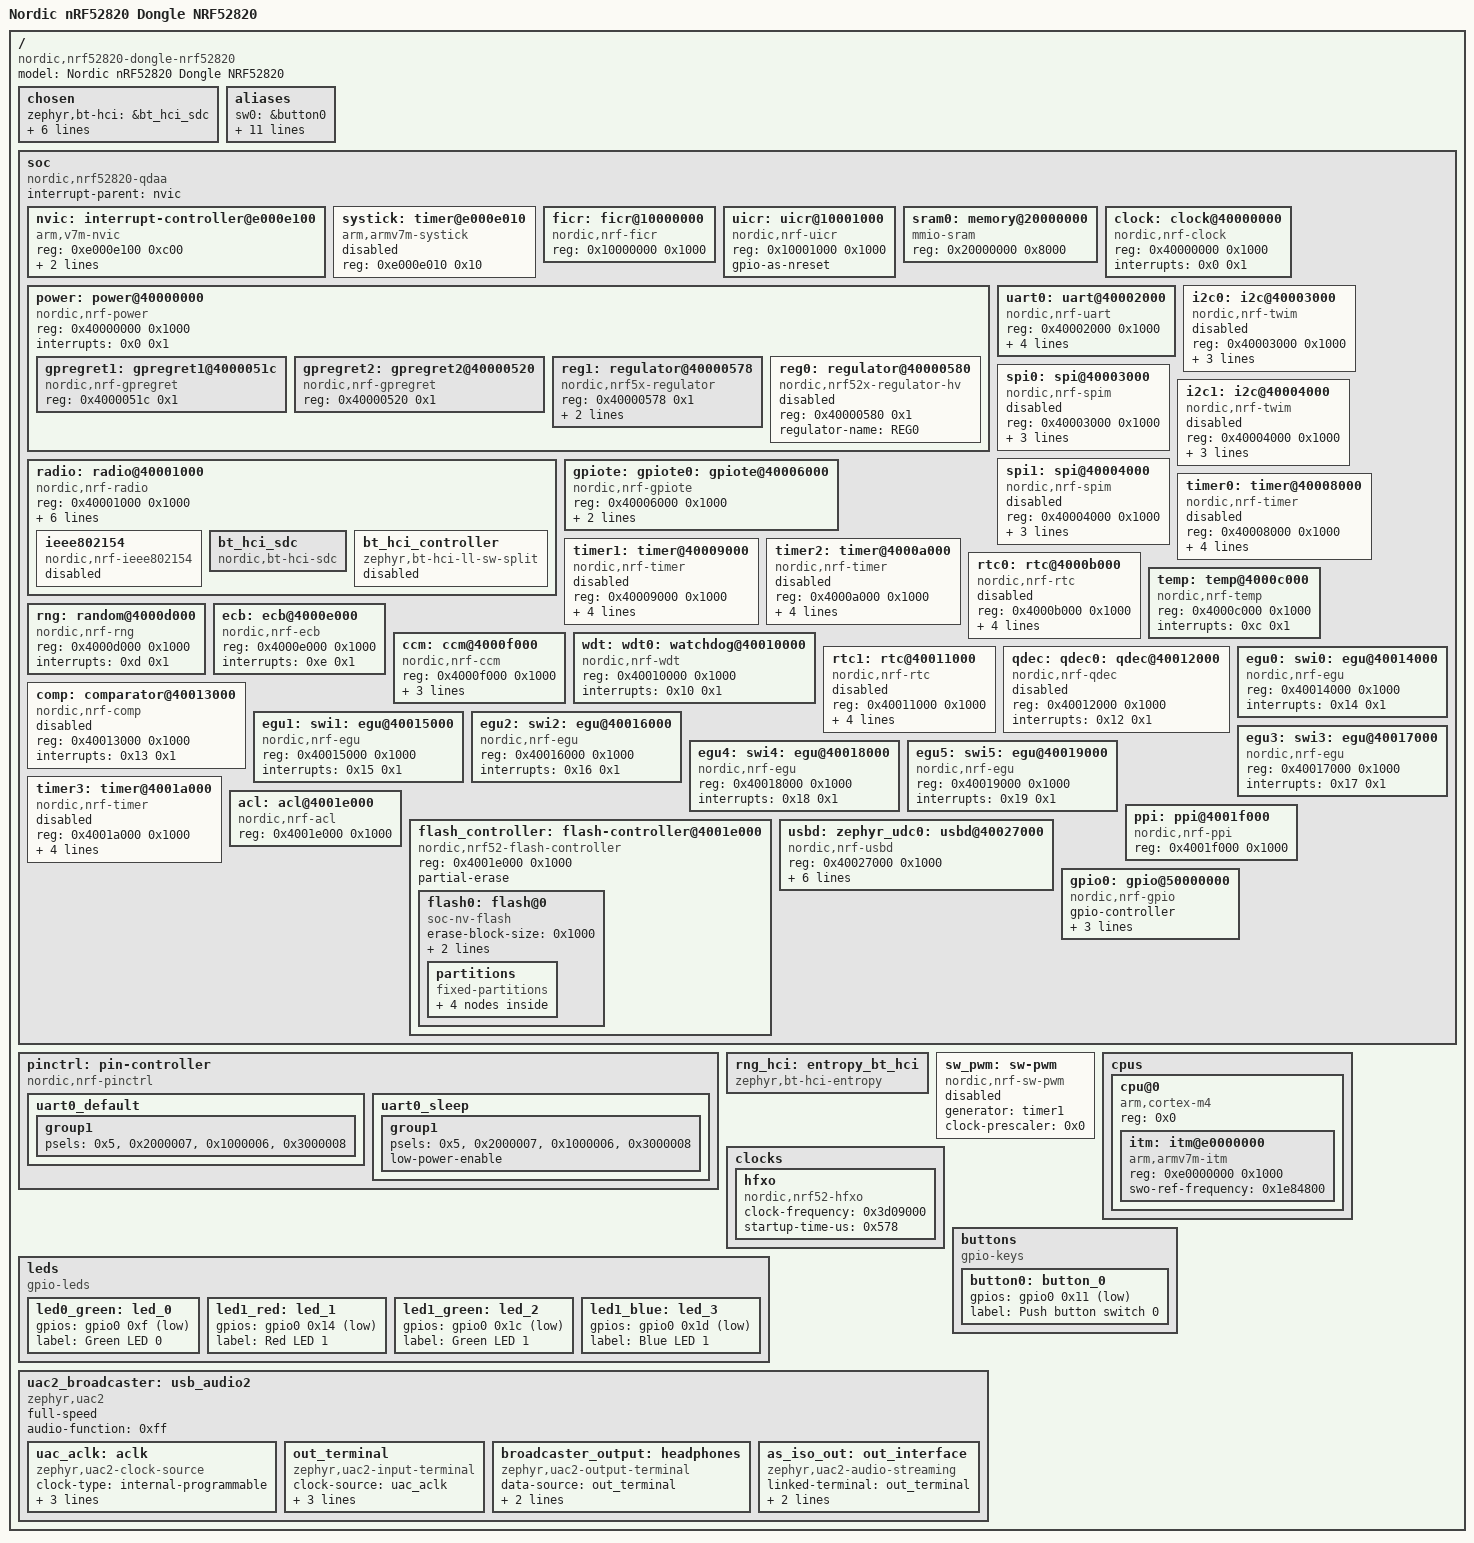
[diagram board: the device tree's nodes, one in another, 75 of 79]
/dts-v1/;

/* node '/' defined in zephyr\dts\common\skeleton.dtsi:9 */
/ {
	#address-cells = < 0x1 >;                       /* in zephyr\dts\common\skeleton.dtsi:10 */
	#size-cells = < 0x1 >;                          /* in zephyr\dts\common\skeleton.dtsi:11 */
	model = "Nordic nRF52820 Dongle NRF52820";      /* in nrf\boards\nordic\nrf52820dongle\nrf52820dongle_nrf52820.dts:11 */
	compatible = "nordic,nrf52820-dongle-nrf52820"; /* in nrf\boards\nordic\nrf52820dongle\nrf52820dongle_nrf52820.dts:12 */

	/* node '/chosen' defined in zephyr\dts\common\skeleton.dtsi:12 */
	chosen {
		zephyr,bt-hci = &bt_hci_sdc;                 /* in zephyr\dts\arm\nordic\nrf52820.dtsi:14 */
		zephyr,entropy = &rng;                       /* in zephyr\dts\arm\nordic\nrf52820.dtsi:15 */
		zephyr,flash-controller = &flash_controller; /* in zephyr\dts\arm\nordic\nrf52820.dtsi:16 */
		zephyr,console = &uart0;                     /* in nrf\boards\nordic\nrf52820dongle\nrf52820dongle_nrf52820.dts:15 */
		zephyr,sram = &sram0;                        /* in nrf\boards\nordic\nrf52820dongle\nrf52820dongle_nrf52820.dts:16 */
		zephyr,flash = &flash0;                      /* in nrf\boards\nordic\nrf52820dongle\nrf52820dongle_nrf52820.dts:17 */
		zephyr,code-partition = &slot0_partition;    /* in nrf\boards\nordic\nrf52820dongle\nrf52820dongle_nrf52820.dts:18 */
	};

	/* node '/aliases' defined in zephyr\dts\common\skeleton.dtsi:13 */
	aliases {
		sw0 = &button0;             /* in nrf\boards\nordic\nrf52820dongle\nrf52820dongle_nrf52820.dts:51 */
		led0 = &led0_green;         /* in nrf\boards\nordic\nrf52820dongle\nrf52820dongle_nrf52820.dts:52 */
		led1 = &led1_red;           /* in nrf\boards\nordic\nrf52820dongle\nrf52820dongle_nrf52820.dts:53 */
		led2 = &led1_green;         /* in nrf\boards\nordic\nrf52820dongle\nrf52820dongle_nrf52820.dts:54 */
		led3 = &led1_blue;          /* in nrf\boards\nordic\nrf52820dongle\nrf52820dongle_nrf52820.dts:55 */
		led0-green = &led0_green;   /* in nrf\boards\nordic\nrf52820dongle\nrf52820dongle_nrf52820.dts:56 */
		led1-red = &led1_red;       /* in nrf\boards\nordic\nrf52820dongle\nrf52820dongle_nrf52820.dts:57 */
		led1-green = &led1_green;   /* in nrf\boards\nordic\nrf52820dongle\nrf52820dongle_nrf52820.dts:58 */
		led1-blue = &led1_blue;     /* in nrf\boards\nordic\nrf52820dongle\nrf52820dongle_nrf52820.dts:59 */
		mcuboot-button0 = &button0; /* in nrf\boards\nordic\nrf52820dongle\nrf52820dongle_nrf52820.dts:60 */
		mcuboot-led0 = &led1_blue;  /* in nrf\boards\nordic\nrf52820dongle\nrf52820dongle_nrf52820.dts:61 */
		watchdog0 = &wdt0;          /* in nrf\boards\nordic\nrf52820dongle\nrf52820dongle_nrf52820.dts:62 */
	};

	/* node '/soc' defined in zephyr\dts\arm\armv7-m.dtsi:6 */
	soc {
		#address-cells = < 0x1 >;            /* in zephyr\dts\arm\armv7-m.dtsi:7 */
		#size-cells = < 0x1 >;               /* in zephyr\dts\arm\armv7-m.dtsi:8 */
		compatible = "nordic,nrf52820-qdaa",
		             "nordic,nrf52820",
		             "nordic,nrf52",
		             "simple-bus";           /* in zephyr\dts\arm\nordic\nrf52820_qdaa.dtsi:20 */
		interrupt-parent = < &nvic >;        /* in zephyr\dts\arm\armv7-m.dtsi:10 */
		ranges;                              /* in zephyr\dts\arm\armv7-m.dtsi:11 */

		/* node '/soc/interrupt-controller@e000e100' defined in zephyr\dts\arm\armv7-m.dtsi:13 */
		nvic: interrupt-controller@e000e100 {
			#address-cells = < 0x1 >;            /* in zephyr\dts\arm\armv7-m.dtsi:14 */
			compatible = "arm,v7m-nvic";         /* in zephyr\dts\arm\armv7-m.dtsi:15 */
			reg = < 0xe000e100 0xc00 >;          /* in zephyr\dts\arm\armv7-m.dtsi:16 */
			interrupt-controller;                /* in zephyr\dts\arm\armv7-m.dtsi:17 */
			#interrupt-cells = < 0x2 >;          /* in zephyr\dts\arm\armv7-m.dtsi:18 */
			arm,num-irq-priority-bits = < 0x3 >; /* in zephyr\dts\arm\nordic\nrf52820.dtsi:433 */
			phandle = < 0x1 >;                   /* in zephyr\dts\arm\armv7-m.dtsi:10 */
		};

		/* node '/soc/timer@e000e010' defined in zephyr\dts\arm\armv7-m.dtsi:21 */
		systick: timer@e000e010 {
			compatible = "arm,armv7m-systick"; /* in zephyr\dts\arm\armv7-m.dtsi:22 */
			reg = < 0xe000e010 0x10 >;         /* in zephyr\dts\arm\armv7-m.dtsi:23 */
			status = "disabled";               /* in zephyr\dts\arm\nordic\nrf52820.dtsi:438 */
		};

		/* node '/soc/ficr@10000000' defined in zephyr\dts\arm\nordic\nrf52820.dtsi:48 */
		ficr: ficr@10000000 {
			compatible = "nordic,nrf-ficr"; /* in zephyr\dts\arm\nordic\nrf52820.dtsi:49 */
			reg = < 0x10000000 0x1000 >;    /* in zephyr\dts\arm\nordic\nrf52820.dtsi:50 */
			#nordic,ficr-cells = < 0x1 >;   /* in zephyr\dts\arm\nordic\nrf52820.dtsi:51 */
			status = "okay";                /* in zephyr\dts\arm\nordic\nrf52820.dtsi:52 */
		};

		/* node '/soc/uicr@10001000' defined in zephyr\dts\arm\nordic\nrf52820.dtsi:55 */
		uicr: uicr@10001000 {
			compatible = "nordic,nrf-uicr"; /* in zephyr\dts\arm\nordic\nrf52820.dtsi:56 */
			reg = < 0x10001000 0x1000 >;    /* in zephyr\dts\arm\nordic\nrf52820.dtsi:57 */
			status = "okay";                /* in zephyr\dts\arm\nordic\nrf52820.dtsi:58 */
			gpio-as-nreset;                 /* in nrf\boards\nordic\nrf52820dongle\nrf52820dongle_nrf52820.dts:71 */
		};

		/* node '/soc/memory@20000000' defined in zephyr\dts\arm\nordic\nrf52820.dtsi:61 */
		sram0: memory@20000000 {
			compatible = "mmio-sram";    /* in zephyr\dts\arm\nordic\nrf52820.dtsi:62 */
			reg = < 0x20000000 0x8000 >; /* in zephyr\dts\arm\nordic\nrf52820_qdaa.dtsi:15 */
		};

		/* node '/soc/clock@40000000' defined in zephyr\dts\arm\nordic\nrf52820.dtsi:65 */
		clock: clock@40000000 {
			compatible = "nordic,nrf-clock"; /* in zephyr\dts\arm\nordic\nrf52820.dtsi:66 */
			reg = < 0x40000000 0x1000 >;     /* in zephyr\dts\arm\nordic\nrf52820.dtsi:67 */
			interrupts = < 0x0 0x1 >;        /* in zephyr\dts\arm\nordic\nrf52820.dtsi:68 */
			status = "okay";                 /* in zephyr\dts\arm\nordic\nrf52820.dtsi:69 */
		};

		/* node '/soc/power@40000000' defined in zephyr\dts\arm\nordic\nrf52820.dtsi:72 */
		power: power@40000000 {
			compatible = "nordic,nrf-power"; /* in zephyr\dts\arm\nordic\nrf52820.dtsi:73 */
			reg = < 0x40000000 0x1000 >;     /* in zephyr\dts\arm\nordic\nrf52820.dtsi:74 */
			interrupts = < 0x0 0x1 >;        /* in zephyr\dts\arm\nordic\nrf52820.dtsi:75 */
			status = "okay";                 /* in zephyr\dts\arm\nordic\nrf52820.dtsi:76 */
			#address-cells = < 0x1 >;        /* in zephyr\dts\arm\nordic\nrf52820.dtsi:77 */
			#size-cells = < 0x1 >;           /* in zephyr\dts\arm\nordic\nrf52820.dtsi:78 */

			/* node '/soc/power@40000000/gpregret1@4000051c' defined in zephyr\dts\arm\nordic\nrf52820.dtsi:80 */
			gpregret1: gpregret1@4000051c {
				#address-cells = < 0x1 >;           /* in zephyr\dts\arm\nordic\nrf52820.dtsi:81 */
				#size-cells = < 0x1 >;              /* in zephyr\dts\arm\nordic\nrf52820.dtsi:82 */
				compatible = "nordic,nrf-gpregret"; /* in zephyr\dts\arm\nordic\nrf52820.dtsi:83 */
				reg = < 0x4000051c 0x1 >;           /* in zephyr\dts\arm\nordic\nrf52820.dtsi:84 */
				status = "okay";                    /* in zephyr\dts\arm\nordic\nrf52820.dtsi:85 */
			};

			/* node '/soc/power@40000000/gpregret2@40000520' defined in zephyr\dts\arm\nordic\nrf52820.dtsi:88 */
			gpregret2: gpregret2@40000520 {
				#address-cells = < 0x1 >;           /* in zephyr\dts\arm\nordic\nrf52820.dtsi:89 */
				#size-cells = < 0x1 >;              /* in zephyr\dts\arm\nordic\nrf52820.dtsi:90 */
				compatible = "nordic,nrf-gpregret"; /* in zephyr\dts\arm\nordic\nrf52820.dtsi:91 */
				reg = < 0x40000520 0x1 >;           /* in zephyr\dts\arm\nordic\nrf52820.dtsi:92 */
				status = "okay";                    /* in zephyr\dts\arm\nordic\nrf52820.dtsi:93 */
			};

			/* node '/soc/power@40000000/regulator@40000578' defined in zephyr\dts\arm\nordic\nrf52820.dtsi:96 */
			reg1: regulator@40000578 {
				compatible = "nordic,nrf5x-regulator"; /* in zephyr\dts\arm\nordic\nrf52820.dtsi:97 */
				reg = < 0x40000578 0x1 >;              /* in zephyr\dts\arm\nordic\nrf52820.dtsi:98 */
				regulator-name = "REG1";               /* in zephyr\dts\arm\nordic\nrf52820.dtsi:99 */
				regulator-initial-mode = < 0x1 >;      /* in nrf\boards\nordic\nrf52820dongle\nrf52820dongle_nrf52820.dts:67 */
			};

			/* node '/soc/power@40000000/regulator@40000580' defined in zephyr\dts\arm\nordic\nrf52820.dtsi:103 */
			reg0: regulator@40000580 {
				compatible = "nordic,nrf52x-regulator-hv"; /* in zephyr\dts\arm\nordic\nrf52820.dtsi:104 */
				reg = < 0x40000580 0x1 >;                  /* in zephyr\dts\arm\nordic\nrf52820.dtsi:105 */
				regulator-name = "REG0";                   /* in zephyr\dts\arm\nordic\nrf52820.dtsi:106 */
				status = "disabled";                       /* in zephyr\dts\arm\nordic\nrf52820.dtsi:107 */
			};
		};

		/* node '/soc/radio@40001000' defined in zephyr\dts\arm\nordic\nrf52820.dtsi:111 */
		radio: radio@40001000 {
			compatible = "nordic,nrf-radio"; /* in zephyr\dts\arm\nordic\nrf52820.dtsi:112 */
			reg = < 0x40001000 0x1000 >;     /* in zephyr\dts\arm\nordic\nrf52820.dtsi:113 */
			interrupts = < 0x1 0x1 >;        /* in zephyr\dts\arm\nordic\nrf52820.dtsi:114 */
			status = "okay";                 /* in zephyr\dts\arm\nordic\nrf52820.dtsi:115 */
			dfe-supported;                   /* in zephyr\dts\arm\nordic\nrf52820.dtsi:116 */
			ieee802154-supported;            /* in zephyr\dts\arm\nordic\nrf52820.dtsi:117 */
			ble-2mbps-supported;             /* in zephyr\dts\arm\nordic\nrf52820.dtsi:118 */
			ble-coded-phy-supported;         /* in zephyr\dts\arm\nordic\nrf52820.dtsi:119 */
			tx-high-power-supported;         /* in zephyr\dts\arm\nordic\nrf52820.dtsi:120 */

			/* node '/soc/radio@40001000/ieee802154' defined in zephyr\dts\arm\nordic\nrf52820.dtsi:122 */
			ieee802154: ieee802154 {
				compatible = "nordic,nrf-ieee802154"; /* in zephyr\dts\arm\nordic\nrf52820.dtsi:123 */
				status = "disabled";                  /* in zephyr\dts\arm\nordic\nrf52820.dtsi:124 */
			};

			/* node '/soc/radio@40001000/bt_hci_sdc' defined in zephyr\dts\arm\nordic\nrf52820.dtsi:127 */
			bt_hci_sdc: bt_hci_sdc {
				compatible = "nordic,bt-hci-sdc"; /* in zephyr\dts\arm\nordic\nrf52820.dtsi:128 */
				status = "okay";                  /* in zephyr\dts\arm\nordic\nrf52820.dtsi:129 */
			};

			/* node '/soc/radio@40001000/bt_hci_controller' defined in zephyr\dts\arm\nordic\nrf52820.dtsi:131 */
			bt_hci_controller: bt_hci_controller {
				compatible = "zephyr,bt-hci-ll-sw-split"; /* in zephyr\dts\arm\nordic\nrf52820.dtsi:132 */
				status = "disabled";                      /* in zephyr\dts\arm\nordic\nrf52820.dtsi:133 */
			};
		};

		/* node '/soc/uart@40002000' defined in zephyr\dts\arm\nordic\nrf52820.dtsi:137 */
		uart0: uart@40002000 {
			compatible = "nordic,nrf-uart"; /* in nrf\boards\nordic\nrf52820dongle\nrf52820dongle_nrf52820.dts:83 */
			reg = < 0x40002000 0x1000 >;    /* in zephyr\dts\arm\nordic\nrf52820.dtsi:141 */
			interrupts = < 0x2 0x1 >;       /* in zephyr\dts\arm\nordic\nrf52820.dtsi:142 */
			status = "okay";                /* in nrf\boards\nordic\nrf52820dongle\nrf52820dongle_nrf52820.dts:84 */
			current-speed = < 0x1c200 >;    /* in nrf\boards\nordic\nrf52820dongle\nrf52820dongle_nrf52820.dts:85 */
			pinctrl-0 = < &uart0_default >; /* in nrf\boards\nordic\nrf52820dongle\nrf52820dongle_nrf52820.dts:86 */
			pinctrl-1 = < &uart0_sleep >;   /* in nrf\boards\nordic\nrf52820dongle\nrf52820dongle_nrf52820.dts:87 */
			pinctrl-names = "default",
			                "sleep";        /* in nrf\boards\nordic\nrf52820dongle\nrf52820dongle_nrf52820.dts:88 */
		};

		/* node '/soc/i2c@40003000' defined in zephyr\dts\arm\nordic\nrf52820.dtsi:146 */
		i2c0: i2c@40003000 {
			compatible = "nordic,nrf-twim"; /* in zephyr\dts\arm\nordic\nrf52820.dtsi:154 */
			#address-cells = < 0x1 >;       /* in zephyr\dts\arm\nordic\nrf52820.dtsi:155 */
			#size-cells = < 0x0 >;          /* in zephyr\dts\arm\nordic\nrf52820.dtsi:156 */
			reg = < 0x40003000 0x1000 >;    /* in zephyr\dts\arm\nordic\nrf52820.dtsi:157 */
			interrupts = < 0x3 0x1 >;       /* in zephyr\dts\arm\nordic\nrf52820.dtsi:158 */
			easydma-maxcnt-bits = < 0xf >;  /* in zephyr\dts\arm\nordic\nrf52820.dtsi:159 */
			status = "disabled";            /* in zephyr\dts\arm\nordic\nrf52820.dtsi:160 */
			zephyr,pm-device-runtime-auto;  /* in zephyr\dts\arm\nordic\nrf52820.dtsi:161 */
		};

		/* node '/soc/spi@40003000' defined in zephyr\dts\arm\nordic\nrf52820.dtsi:164 */
		spi0: spi@40003000 {
			compatible = "nordic,nrf-spim"; /* in zephyr\dts\arm\nordic\nrf52820.dtsi:172 */
			#address-cells = < 0x1 >;       /* in zephyr\dts\arm\nordic\nrf52820.dtsi:173 */
			#size-cells = < 0x0 >;          /* in zephyr\dts\arm\nordic\nrf52820.dtsi:174 */
			reg = < 0x40003000 0x1000 >;    /* in zephyr\dts\arm\nordic\nrf52820.dtsi:175 */
			interrupts = < 0x3 0x1 >;       /* in zephyr\dts\arm\nordic\nrf52820.dtsi:176 */
			max-frequency = < 0x7a1200 >;   /* in zephyr\dts\arm\nordic\nrf52820.dtsi:177 */
			easydma-maxcnt-bits = < 0xf >;  /* in zephyr\dts\arm\nordic\nrf52820.dtsi:178 */
			status = "disabled";            /* in zephyr\dts\arm\nordic\nrf52820.dtsi:179 */
		};

		/* node '/soc/i2c@40004000' defined in zephyr\dts\arm\nordic\nrf52820.dtsi:182 */
		i2c1: i2c@40004000 {
			compatible = "nordic,nrf-twim"; /* in zephyr\dts\arm\nordic\nrf52820.dtsi:190 */
			#address-cells = < 0x1 >;       /* in zephyr\dts\arm\nordic\nrf52820.dtsi:191 */
			#size-cells = < 0x0 >;          /* in zephyr\dts\arm\nordic\nrf52820.dtsi:192 */
			reg = < 0x40004000 0x1000 >;    /* in zephyr\dts\arm\nordic\nrf52820.dtsi:193 */
			interrupts = < 0x4 0x1 >;       /* in zephyr\dts\arm\nordic\nrf52820.dtsi:194 */
			easydma-maxcnt-bits = < 0xf >;  /* in zephyr\dts\arm\nordic\nrf52820.dtsi:195 */
			status = "disabled";            /* in zephyr\dts\arm\nordic\nrf52820.dtsi:196 */
			zephyr,pm-device-runtime-auto;  /* in zephyr\dts\arm\nordic\nrf52820.dtsi:197 */
		};

		/* node '/soc/spi@40004000' defined in zephyr\dts\arm\nordic\nrf52820.dtsi:200 */
		spi1: spi@40004000 {
			compatible = "nordic,nrf-spim"; /* in zephyr\dts\arm\nordic\nrf52820.dtsi:208 */
			#address-cells = < 0x1 >;       /* in zephyr\dts\arm\nordic\nrf52820.dtsi:209 */
			#size-cells = < 0x0 >;          /* in zephyr\dts\arm\nordic\nrf52820.dtsi:210 */
			reg = < 0x40004000 0x1000 >;    /* in zephyr\dts\arm\nordic\nrf52820.dtsi:211 */
			interrupts = < 0x4 0x1 >;       /* in zephyr\dts\arm\nordic\nrf52820.dtsi:212 */
			max-frequency = < 0x7a1200 >;   /* in zephyr\dts\arm\nordic\nrf52820.dtsi:213 */
			easydma-maxcnt-bits = < 0xf >;  /* in zephyr\dts\arm\nordic\nrf52820.dtsi:214 */
			status = "disabled";            /* in zephyr\dts\arm\nordic\nrf52820.dtsi:215 */
		};

		/* node '/soc/gpiote@40006000' defined in zephyr\dts\arm\nordic\nrf52820.dtsi:218 */
		gpiote: gpiote0: gpiote@40006000 {
			compatible = "nordic,nrf-gpiote"; /* in zephyr\dts\arm\nordic\nrf52820.dtsi:219 */
			reg = < 0x40006000 0x1000 >;      /* in zephyr\dts\arm\nordic\nrf52820.dtsi:220 */
			interrupts = < 0x6 0x5 >;         /* in zephyr\dts\arm\nordic\nrf52820.dtsi:221 */
			status = "okay";                  /* in nrf\boards\nordic\nrf52820dongle\nrf52820dongle_nrf52820.dts:75 */
			instance = < 0x0 >;               /* in zephyr\dts\arm\nordic\nrf52820.dtsi:223 */
			phandle = < 0x4 >;                /* in zephyr\dts\arm\nordic\nrf52820.dtsi:427 */
		};

		/* node '/soc/timer@40008000' defined in zephyr\dts\arm\nordic\nrf52820.dtsi:226 */
		timer0: timer@40008000 {
			compatible = "nordic,nrf-timer"; /* in zephyr\dts\arm\nordic\nrf52820.dtsi:227 */
			status = "disabled";             /* in zephyr\dts\arm\nordic\nrf52820.dtsi:228 */
			reg = < 0x40008000 0x1000 >;     /* in zephyr\dts\arm\nordic\nrf52820.dtsi:229 */
			cc-num = < 0x4 >;                /* in zephyr\dts\arm\nordic\nrf52820.dtsi:230 */
			max-bit-width = < 0x20 >;        /* in zephyr\dts\arm\nordic\nrf52820.dtsi:231 */
			interrupts = < 0x8 0x1 >;        /* in zephyr\dts\arm\nordic\nrf52820.dtsi:232 */
			prescaler = < 0x0 >;             /* in zephyr\dts\arm\nordic\nrf52820.dtsi:233 */
		};

		/* node '/soc/timer@40009000' defined in zephyr\dts\arm\nordic\nrf52820.dtsi:236 */
		timer1: timer@40009000 {
			compatible = "nordic,nrf-timer"; /* in zephyr\dts\arm\nordic\nrf52820.dtsi:237 */
			status = "disabled";             /* in zephyr\dts\arm\nordic\nrf52820.dtsi:238 */
			reg = < 0x40009000 0x1000 >;     /* in zephyr\dts\arm\nordic\nrf52820.dtsi:239 */
			cc-num = < 0x4 >;                /* in zephyr\dts\arm\nordic\nrf52820.dtsi:240 */
			max-bit-width = < 0x20 >;        /* in zephyr\dts\arm\nordic\nrf52820.dtsi:241 */
			interrupts = < 0x9 0x1 >;        /* in zephyr\dts\arm\nordic\nrf52820.dtsi:242 */
			prescaler = < 0x0 >;             /* in zephyr\dts\arm\nordic\nrf52820.dtsi:243 */
			phandle = < 0x5 >;               /* in zephyr\dts\vendor\nordic\nrf_common.dtsi:41 */
		};

		/* node '/soc/timer@4000a000' defined in zephyr\dts\arm\nordic\nrf52820.dtsi:246 */
		timer2: timer@4000a000 {
			compatible = "nordic,nrf-timer"; /* in zephyr\dts\arm\nordic\nrf52820.dtsi:247 */
			status = "disabled";             /* in zephyr\dts\arm\nordic\nrf52820.dtsi:248 */
			reg = < 0x4000a000 0x1000 >;     /* in zephyr\dts\arm\nordic\nrf52820.dtsi:249 */
			cc-num = < 0x4 >;                /* in zephyr\dts\arm\nordic\nrf52820.dtsi:250 */
			max-bit-width = < 0x20 >;        /* in zephyr\dts\arm\nordic\nrf52820.dtsi:251 */
			interrupts = < 0xa 0x1 >;        /* in zephyr\dts\arm\nordic\nrf52820.dtsi:252 */
			prescaler = < 0x0 >;             /* in zephyr\dts\arm\nordic\nrf52820.dtsi:253 */
		};

		/* node '/soc/rtc@4000b000' defined in zephyr\dts\arm\nordic\nrf52820.dtsi:256 */
		rtc0: rtc@4000b000 {
			compatible = "nordic,nrf-rtc"; /* in zephyr\dts\arm\nordic\nrf52820.dtsi:257 */
			reg = < 0x4000b000 0x1000 >;   /* in zephyr\dts\arm\nordic\nrf52820.dtsi:258 */
			cc-num = < 0x3 >;              /* in zephyr\dts\arm\nordic\nrf52820.dtsi:259 */
			interrupts = < 0xb 0x1 >;      /* in zephyr\dts\arm\nordic\nrf52820.dtsi:260 */
			status = "disabled";           /* in zephyr\dts\arm\nordic\nrf52820.dtsi:261 */
			clock-frequency = < 0x8000 >;  /* in zephyr\dts\arm\nordic\nrf52820.dtsi:262 */
			prescaler = < 0x1 >;           /* in zephyr\dts\arm\nordic\nrf52820.dtsi:263 */
		};

		/* node '/soc/temp@4000c000' defined in zephyr\dts\arm\nordic\nrf52820.dtsi:266 */
		temp: temp@4000c000 {
			compatible = "nordic,nrf-temp"; /* in zephyr\dts\arm\nordic\nrf52820.dtsi:267 */
			reg = < 0x4000c000 0x1000 >;    /* in zephyr\dts\arm\nordic\nrf52820.dtsi:268 */
			interrupts = < 0xc 0x1 >;       /* in zephyr\dts\arm\nordic\nrf52820.dtsi:269 */
			status = "okay";                /* in zephyr\dts\arm\nordic\nrf52820.dtsi:270 */
		};

		/* node '/soc/random@4000d000' defined in zephyr\dts\arm\nordic\nrf52820.dtsi:273 */
		rng: random@4000d000 {
			compatible = "nordic,nrf-rng"; /* in zephyr\dts\arm\nordic\nrf52820.dtsi:274 */
			reg = < 0x4000d000 0x1000 >;   /* in zephyr\dts\arm\nordic\nrf52820.dtsi:275 */
			interrupts = < 0xd 0x1 >;      /* in zephyr\dts\arm\nordic\nrf52820.dtsi:276 */
			status = "okay";               /* in zephyr\dts\arm\nordic\nrf52820.dtsi:277 */
		};

		/* node '/soc/ecb@4000e000' defined in zephyr\dts\arm\nordic\nrf52820.dtsi:280 */
		ecb: ecb@4000e000 {
			compatible = "nordic,nrf-ecb"; /* in zephyr\dts\arm\nordic\nrf52820.dtsi:281 */
			reg = < 0x4000e000 0x1000 >;   /* in zephyr\dts\arm\nordic\nrf52820.dtsi:282 */
			interrupts = < 0xe 0x1 >;      /* in zephyr\dts\arm\nordic\nrf52820.dtsi:283 */
			status = "okay";               /* in zephyr\dts\arm\nordic\nrf52820.dtsi:284 */
		};

		/* node '/soc/ccm@4000f000' defined in zephyr\dts\arm\nordic\nrf52820.dtsi:287 */
		ccm: ccm@4000f000 {
			compatible = "nordic,nrf-ccm"; /* in zephyr\dts\arm\nordic\nrf52820.dtsi:288 */
			reg = < 0x4000f000 0x1000 >;   /* in zephyr\dts\arm\nordic\nrf52820.dtsi:289 */
			interrupts = < 0xf 0x1 >;      /* in zephyr\dts\arm\nordic\nrf52820.dtsi:290 */
			length-field-length-8-bits;    /* in zephyr\dts\arm\nordic\nrf52820.dtsi:291 */
			headermask-supported;          /* in zephyr\dts\arm\nordic\nrf52820.dtsi:292 */
			status = "okay";               /* in zephyr\dts\arm\nordic\nrf52820.dtsi:293 */
		};

		/* node '/soc/watchdog@40010000' defined in zephyr\dts\arm\nordic\nrf52820.dtsi:296 */
		wdt: wdt0: watchdog@40010000 {
			compatible = "nordic,nrf-wdt"; /* in zephyr\dts\arm\nordic\nrf52820.dtsi:297 */
			reg = < 0x40010000 0x1000 >;   /* in zephyr\dts\arm\nordic\nrf52820.dtsi:298 */
			interrupts = < 0x10 0x1 >;     /* in zephyr\dts\arm\nordic\nrf52820.dtsi:299 */
			status = "okay";               /* in zephyr\dts\arm\nordic\nrf52820.dtsi:300 */
		};

		/* node '/soc/rtc@40011000' defined in zephyr\dts\arm\nordic\nrf52820.dtsi:303 */
		rtc1: rtc@40011000 {
			compatible = "nordic,nrf-rtc"; /* in zephyr\dts\arm\nordic\nrf52820.dtsi:304 */
			reg = < 0x40011000 0x1000 >;   /* in zephyr\dts\arm\nordic\nrf52820.dtsi:305 */
			cc-num = < 0x4 >;              /* in zephyr\dts\arm\nordic\nrf52820.dtsi:306 */
			interrupts = < 0x11 0x1 >;     /* in zephyr\dts\arm\nordic\nrf52820.dtsi:307 */
			status = "disabled";           /* in zephyr\dts\arm\nordic\nrf52820.dtsi:308 */
			clock-frequency = < 0x8000 >;  /* in zephyr\dts\arm\nordic\nrf52820.dtsi:309 */
			prescaler = < 0x1 >;           /* in zephyr\dts\arm\nordic\nrf52820.dtsi:310 */
		};

		/* node '/soc/qdec@40012000' defined in zephyr\dts\arm\nordic\nrf52820.dtsi:313 */
		qdec: qdec0: qdec@40012000 {
			compatible = "nordic,nrf-qdec"; /* in zephyr\dts\arm\nordic\nrf52820.dtsi:314 */
			reg = < 0x40012000 0x1000 >;    /* in zephyr\dts\arm\nordic\nrf52820.dtsi:315 */
			interrupts = < 0x12 0x1 >;      /* in zephyr\dts\arm\nordic\nrf52820.dtsi:316 */
			status = "disabled";            /* in zephyr\dts\arm\nordic\nrf52820.dtsi:317 */
		};

		/* node '/soc/comparator@40013000' defined in zephyr\dts\arm\nordic\nrf52820.dtsi:320 */
		comp: comparator@40013000 {
			compatible = "nordic,nrf-comp"; /* in zephyr\dts\arm\nordic\nrf52820.dtsi:321 */
			reg = < 0x40013000 0x1000 >;    /* in zephyr\dts\arm\nordic\nrf52820.dtsi:322 */
			interrupts = < 0x13 0x1 >;      /* in zephyr\dts\arm\nordic\nrf52820.dtsi:323 */
			status = "disabled";            /* in zephyr\dts\arm\nordic\nrf52820.dtsi:324 */
		};

		/* node '/soc/egu@40014000' defined in zephyr\dts\arm\nordic\nrf52820.dtsi:327 */
		egu0: swi0: egu@40014000 {
			compatible = "nordic,nrf-egu",
			             "nordic,nrf-swi"; /* in zephyr\dts\arm\nordic\nrf52820.dtsi:328 */
			reg = < 0x40014000 0x1000 >;   /* in zephyr\dts\arm\nordic\nrf52820.dtsi:329 */
			interrupts = < 0x14 0x1 >;     /* in zephyr\dts\arm\nordic\nrf52820.dtsi:330 */
			status = "okay";               /* in zephyr\dts\arm\nordic\nrf52820.dtsi:331 */
		};

		/* node '/soc/egu@40015000' defined in zephyr\dts\arm\nordic\nrf52820.dtsi:334 */
		egu1: swi1: egu@40015000 {
			compatible = "nordic,nrf-egu",
			             "nordic,nrf-swi"; /* in zephyr\dts\arm\nordic\nrf52820.dtsi:335 */
			reg = < 0x40015000 0x1000 >;   /* in zephyr\dts\arm\nordic\nrf52820.dtsi:336 */
			interrupts = < 0x15 0x1 >;     /* in zephyr\dts\arm\nordic\nrf52820.dtsi:337 */
			status = "okay";               /* in zephyr\dts\arm\nordic\nrf52820.dtsi:338 */
		};

		/* node '/soc/egu@40016000' defined in zephyr\dts\arm\nordic\nrf52820.dtsi:341 */
		egu2: swi2: egu@40016000 {
			compatible = "nordic,nrf-egu",
			             "nordic,nrf-swi"; /* in zephyr\dts\arm\nordic\nrf52820.dtsi:342 */
			reg = < 0x40016000 0x1000 >;   /* in zephyr\dts\arm\nordic\nrf52820.dtsi:343 */
			interrupts = < 0x16 0x1 >;     /* in zephyr\dts\arm\nordic\nrf52820.dtsi:344 */
			status = "okay";               /* in zephyr\dts\arm\nordic\nrf52820.dtsi:345 */
		};

		/* node '/soc/egu@40017000' defined in zephyr\dts\arm\nordic\nrf52820.dtsi:348 */
		egu3: swi3: egu@40017000 {
			compatible = "nordic,nrf-egu",
			             "nordic,nrf-swi"; /* in zephyr\dts\arm\nordic\nrf52820.dtsi:349 */
			reg = < 0x40017000 0x1000 >;   /* in zephyr\dts\arm\nordic\nrf52820.dtsi:350 */
			interrupts = < 0x17 0x1 >;     /* in zephyr\dts\arm\nordic\nrf52820.dtsi:351 */
			status = "okay";               /* in zephyr\dts\arm\nordic\nrf52820.dtsi:352 */
		};

		/* node '/soc/egu@40018000' defined in zephyr\dts\arm\nordic\nrf52820.dtsi:355 */
		egu4: swi4: egu@40018000 {
			compatible = "nordic,nrf-egu",
			             "nordic,nrf-swi"; /* in zephyr\dts\arm\nordic\nrf52820.dtsi:356 */
			reg = < 0x40018000 0x1000 >;   /* in zephyr\dts\arm\nordic\nrf52820.dtsi:357 */
			interrupts = < 0x18 0x1 >;     /* in zephyr\dts\arm\nordic\nrf52820.dtsi:358 */
			status = "okay";               /* in zephyr\dts\arm\nordic\nrf52820.dtsi:359 */
		};

		/* node '/soc/egu@40019000' defined in zephyr\dts\arm\nordic\nrf52820.dtsi:362 */
		egu5: swi5: egu@40019000 {
			compatible = "nordic,nrf-egu",
			             "nordic,nrf-swi"; /* in zephyr\dts\arm\nordic\nrf52820.dtsi:363 */
			reg = < 0x40019000 0x1000 >;   /* in zephyr\dts\arm\nordic\nrf52820.dtsi:364 */
			interrupts = < 0x19 0x1 >;     /* in zephyr\dts\arm\nordic\nrf52820.dtsi:365 */
			status = "okay";               /* in zephyr\dts\arm\nordic\nrf52820.dtsi:366 */
		};

		/* node '/soc/timer@4001a000' defined in zephyr\dts\arm\nordic\nrf52820.dtsi:369 */
		timer3: timer@4001a000 {
			compatible = "nordic,nrf-timer"; /* in zephyr\dts\arm\nordic\nrf52820.dtsi:370 */
			status = "disabled";             /* in zephyr\dts\arm\nordic\nrf52820.dtsi:371 */
			reg = < 0x4001a000 0x1000 >;     /* in zephyr\dts\arm\nordic\nrf52820.dtsi:372 */
			cc-num = < 0x6 >;                /* in zephyr\dts\arm\nordic\nrf52820.dtsi:373 */
			max-bit-width = < 0x20 >;        /* in zephyr\dts\arm\nordic\nrf52820.dtsi:374 */
			interrupts = < 0x1a 0x1 >;       /* in zephyr\dts\arm\nordic\nrf52820.dtsi:375 */
			prescaler = < 0x0 >;             /* in zephyr\dts\arm\nordic\nrf52820.dtsi:376 */
		};

		/* node '/soc/acl@4001e000' defined in zephyr\dts\arm\nordic\nrf52820.dtsi:379 */
		acl: acl@4001e000 {
			compatible = "nordic,nrf-acl"; /* in zephyr\dts\arm\nordic\nrf52820.dtsi:380 */
			reg = < 0x4001e000 0x1000 >;   /* in zephyr\dts\arm\nordic\nrf52820.dtsi:381 */
			status = "okay";               /* in zephyr\dts\arm\nordic\nrf52820.dtsi:382 */
		};

		/* node '/soc/flash-controller@4001e000' defined in zephyr\dts\arm\nordic\nrf52820.dtsi:385 */
		flash_controller: flash-controller@4001e000 {
			compatible = "nordic,nrf52-flash-controller"; /* in zephyr\dts\arm\nordic\nrf52820.dtsi:386 */
			reg = < 0x4001e000 0x1000 >;                  /* in zephyr\dts\arm\nordic\nrf52820.dtsi:387 */
			partial-erase;                                /* in zephyr\dts\arm\nordic\nrf52820.dtsi:388 */
			#address-cells = < 0x1 >;                     /* in zephyr\dts\arm\nordic\nrf52820.dtsi:390 */
			#size-cells = < 0x1 >;                        /* in zephyr\dts\arm\nordic\nrf52820.dtsi:391 */

			/* node '/soc/flash-controller@4001e000/flash@0' defined in zephyr\dts\arm\nordic\nrf52820.dtsi:394 */
			flash0: flash@0 {
				compatible = "soc-nv-flash";   /* in zephyr\dts\arm\nordic\nrf52820.dtsi:395 */
				erase-block-size = < 0x1000 >; /* in zephyr\dts\arm\nordic\nrf52820.dtsi:396 */
				write-block-size = < 0x4 >;    /* in zephyr\dts\arm\nordic\nrf52820.dtsi:397 */
				reg = < 0x0 0x40000 >;         /* in zephyr\dts\arm\nordic\nrf52820_qdaa.dtsi:11 */

				/* node '/soc/flash-controller@4001e000/flash@0/partitions' defined in nrf\boards\nordic\nrf52820dongle\nrf52820dongle_nrf52820.dts:117 */
				partitions {
					compatible = "fixed-partitions"; /* in nrf\boards\nordic\nrf52820dongle\nrf52820dongle_nrf52820.dts:118 */
					#address-cells = < 0x1 >;        /* in nrf\boards\nordic\nrf52820dongle\nrf52820dongle_nrf52820.dts:119 */
					#size-cells = < 0x1 >;           /* in nrf\boards\nordic\nrf52820dongle\nrf52820dongle_nrf52820.dts:120 */

					/* node '/soc/flash-controller@4001e000/flash@0/partitions/partition@0' defined in nrf\boards\nordic\nrf52820dongle\nrf52820dongle_nrf52820.dts:122 */
					boot_partition: partition@0 {
						label = "mcuboot";    /* in nrf\boards\nordic\nrf52820dongle\nrf52820dongle_nrf52820.dts:123 */
						reg = < 0x0 0xd000 >; /* in nrf\boards\nordic\nrf52820dongle\nrf52820dongle_nrf52820.dts:124 */
					};

					/* node '/soc/flash-controller@4001e000/flash@0/partitions/partition@d000' defined in nrf\boards\nordic\nrf52820dongle\nrf52820dongle_nrf52820.dts:126 */
					slot0_partition: partition@d000 {
						label = "image-0";        /* in nrf\boards\nordic\nrf52820dongle\nrf52820dongle_nrf52820.dts:127 */
						reg = < 0xd000 0x30000 >; /* in nrf\boards\nordic\nrf52820dongle\nrf52820dongle_nrf52820.dts:128 */
					};

					/* node '/soc/flash-controller@4001e000/flash@0/partitions/partition@3d000' defined in nrf\boards\nordic\nrf52820dongle\nrf52820dongle_nrf52820.dts:130 */
					slot1_partition: partition@3d000 {
						label = "image-1";        /* in nrf\boards\nordic\nrf52820dongle\nrf52820dongle_nrf52820.dts:131 */
						reg = < 0x3d000 0x1000 >; /* in nrf\boards\nordic\nrf52820dongle\nrf52820dongle_nrf52820.dts:132 */
					};

					/* node '/soc/flash-controller@4001e000/flash@0/partitions/partition@3e000' defined in nrf\boards\nordic\nrf52820dongle\nrf52820dongle_nrf52820.dts:134 */
					storage_partition: partition@3e000 {
						label = "storage";        /* in nrf\boards\nordic\nrf52820dongle\nrf52820dongle_nrf52820.dts:135 */
						reg = < 0x3e000 0x2000 >; /* in nrf\boards\nordic\nrf52820dongle\nrf52820dongle_nrf52820.dts:136 */
					};
				};
			};
		};

		/* node '/soc/ppi@4001f000' defined in zephyr\dts\arm\nordic\nrf52820.dtsi:401 */
		ppi: ppi@4001f000 {
			compatible = "nordic,nrf-ppi"; /* in zephyr\dts\arm\nordic\nrf52820.dtsi:402 */
			reg = < 0x4001f000 0x1000 >;   /* in zephyr\dts\arm\nordic\nrf52820.dtsi:403 */
			status = "okay";               /* in zephyr\dts\arm\nordic\nrf52820.dtsi:404 */
		};

		/* node '/soc/usbd@40027000' defined in zephyr\dts\arm\nordic\nrf52820.dtsi:407 */
		usbd: zephyr_udc0: usbd@40027000 {
			compatible = "nordic,nrf-usbd"; /* in nrf\boards\nordic\nrf52820dongle\nrf52820dongle_nrf52820.dts:142 */
			reg = < 0x40027000 0x1000 >;    /* in zephyr\dts\arm\nordic\nrf52820.dtsi:409 */
			interrupts = < 0x27 0x1 >;      /* in zephyr\dts\arm\nordic\nrf52820.dtsi:410 */
			num-bidir-endpoints = < 0x1 >;  /* in zephyr\dts\arm\nordic\nrf52820.dtsi:411 */
			num-in-endpoints = < 0x7 >;     /* in zephyr\dts\arm\nordic\nrf52820.dtsi:412 */
			num-out-endpoints = < 0x7 >;    /* in zephyr\dts\arm\nordic\nrf52820.dtsi:413 */
			num-isoin-endpoints = < 0x1 >;  /* in zephyr\dts\arm\nordic\nrf52820.dtsi:414 */
			num-isoout-endpoints = < 0x1 >; /* in zephyr\dts\arm\nordic\nrf52820.dtsi:415 */
			status = "okay";                /* in nrf\boards\nordic\nrf52820dongle\nrf52820dongle_nrf52820.dts:143 */
		};

		/* node '/soc/gpio@50000000' defined in zephyr\dts\arm\nordic\nrf52820.dtsi:419 */
		gpio0: gpio@50000000 {
			compatible = "nordic,nrf-gpio";              /* in zephyr\dts\arm\nordic\nrf52820.dtsi:420 */
			gpio-controller;                             /* in zephyr\dts\arm\nordic\nrf52820.dtsi:421 */
			reg = < 0x50000000 0x200 0x50000500 0x300 >; /* in zephyr\dts\arm\nordic\nrf52820.dtsi:422 */
			#gpio-cells = < 0x2 >;                       /* in zephyr\dts\arm\nordic\nrf52820.dtsi:424 */
			status = "okay";                             /* in nrf\boards\nordic\nrf52820dongle\nrf52820dongle_nrf52820.dts:79 */
			port = < 0x0 >;                              /* in zephyr\dts\arm\nordic\nrf52820.dtsi:426 */
			gpiote-instance = < &gpiote >;               /* in zephyr\dts\arm\nordic\nrf52820.dtsi:427 */
			phandle = < 0x6 >;                           /* in nrf\boards\nordic\nrf52820dongle\nrf52820dongle_nrf52820.dts:24 */
		};
	};

	/* node '/pin-controller' defined in zephyr\dts\vendor\nordic\nrf_common.dtsi:25 */
	pinctrl: pin-controller {
		compatible = "nordic,nrf-pinctrl"; /* in zephyr\dts\vendor\nordic\nrf_common.dtsi:30 */

		/* node '/pin-controller/uart0_default' defined in nrf\boards\nordic\nrf52820dongle\nrf52820dongle_nrf52820.dts:92 */
		uart0_default: uart0_default {
			phandle = < 0x2 >; /* in nrf\boards\nordic\nrf52820dongle\nrf52820dongle_nrf52820.dts:86 */

			/* node '/pin-controller/uart0_default/group1' defined in nrf\boards\nordic\nrf52820dongle\nrf52820dongle_nrf52820.dts:93 */
			group1 {
				psels = < 0x5 >,
				        < 0x2000007 >,
				        < 0x1000006 >,
				        < 0x3000008 >; /* in nrf\boards\nordic\nrf52820dongle\nrf52820dongle_nrf52820.dts:94 */
			};
		};

		/* node '/pin-controller/uart0_sleep' defined in nrf\boards\nordic\nrf52820dongle\nrf52820dongle_nrf52820.dts:101 */
		uart0_sleep: uart0_sleep {
			phandle = < 0x3 >; /* in nrf\boards\nordic\nrf52820dongle\nrf52820dongle_nrf52820.dts:87 */

			/* node '/pin-controller/uart0_sleep/group1' defined in nrf\boards\nordic\nrf52820dongle\nrf52820dongle_nrf52820.dts:102 */
			group1 {
				psels = < 0x5 >,
				        < 0x2000007 >,
				        < 0x1000006 >,
				        < 0x3000008 >; /* in nrf\boards\nordic\nrf52820dongle\nrf52820dongle_nrf52820.dts:103 */
				low-power-enable;      /* in nrf\boards\nordic\nrf52820dongle\nrf52820dongle_nrf52820.dts:107 */
			};
		};
	};

	/* node '/entropy_bt_hci' defined in zephyr\dts\vendor\nordic\nrf_common.dtsi:33 */
	rng_hci: entropy_bt_hci {
		compatible = "zephyr,bt-hci-entropy"; /* in zephyr\dts\vendor\nordic\nrf_common.dtsi:34 */
		status = "okay";                      /* in zephyr\dts\vendor\nordic\nrf_common.dtsi:35 */
	};

	/* node '/sw-pwm' defined in zephyr\dts\vendor\nordic\nrf_common.dtsi:38 */
	sw_pwm: sw-pwm {
		compatible = "nordic,nrf-sw-pwm"; /* in zephyr\dts\vendor\nordic\nrf_common.dtsi:39 */
		status = "disabled";              /* in zephyr\dts\vendor\nordic\nrf_common.dtsi:40 */
		generator = < &timer1 >;          /* in zephyr\dts\vendor\nordic\nrf_common.dtsi:41 */
		clock-prescaler = < 0x0 >;        /* in zephyr\dts\vendor\nordic\nrf_common.dtsi:42 */
		#pwm-cells = < 0x3 >;             /* in zephyr\dts\vendor\nordic\nrf_common.dtsi:43 */
	};

	/* node '/cpus' defined in zephyr\dts\arm\nordic\nrf52820.dtsi:19 */
	cpus {
		#address-cells = < 0x1 >; /* in zephyr\dts\arm\nordic\nrf52820.dtsi:20 */
		#size-cells = < 0x0 >;    /* in zephyr\dts\arm\nordic\nrf52820.dtsi:21 */

		/* node '/cpus/cpu@0' defined in zephyr\dts\arm\nordic\nrf52820.dtsi:23 */
		cpu@0 {
			device_type = "cpu";          /* in zephyr\dts\arm\nordic\nrf52820.dtsi:24 */
			compatible = "arm,cortex-m4"; /* in zephyr\dts\arm\nordic\nrf52820.dtsi:25 */
			reg = < 0x0 >;                /* in zephyr\dts\arm\nordic\nrf52820.dtsi:26 */
			#address-cells = < 0x1 >;     /* in zephyr\dts\arm\nordic\nrf52820.dtsi:27 */
			#size-cells = < 0x1 >;        /* in zephyr\dts\arm\nordic\nrf52820.dtsi:28 */

			/* node '/cpus/cpu@0/itm@e0000000' defined in zephyr\dts\arm\nordic\nrf52820.dtsi:30 */
			itm: itm@e0000000 {
				compatible = "arm,armv7m-itm";     /* in zephyr\dts\arm\nordic\nrf52820.dtsi:31 */
				reg = < 0xe0000000 0x1000 >;       /* in zephyr\dts\arm\nordic\nrf52820.dtsi:32 */
				swo-ref-frequency = < 0x1e84800 >; /* in zephyr\dts\arm\nordic\nrf52820.dtsi:33 */
			};
		};
	};

	/* node '/clocks' defined in zephyr\dts\arm\nordic\nrf52820.dtsi:38 */
	clocks {

		/* node '/clocks/hfxo' defined in zephyr\dts\arm\nordic\nrf52820.dtsi:39 */
		hfxo: hfxo {
			compatible = "nordic,nrf52-hfxo"; /* in zephyr\dts\arm\nordic\nrf52820.dtsi:40 */
			clock-frequency = < 0x3d09000 >;  /* in zephyr\dts\arm\nordic\nrf52820.dtsi:41 */
			startup-time-us = < 0x578 >;      /* in zephyr\dts\arm\nordic\nrf52820.dtsi:42 */
			#clock-cells = < 0x0 >;           /* in zephyr\dts\arm\nordic\nrf52820.dtsi:43 */
		};
	};

	/* node '/leds' defined in nrf\boards\nordic\nrf52820dongle\nrf52820dongle_nrf52820.dts:21 */
	leds {
		compatible = "gpio-leds"; /* in nrf\boards\nordic\nrf52820dongle\nrf52820dongle_nrf52820.dts:22 */

		/* node '/leds/led_0' defined in nrf\boards\nordic\nrf52820dongle\nrf52820dongle_nrf52820.dts:23 */
		led0_green: led_0 {
			gpios = < &gpio0 0xf 0x1 >; /* in nrf\boards\nordic\nrf52820dongle\nrf52820dongle_nrf52820.dts:24 */
			label = "Green LED 0";      /* in nrf\boards\nordic\nrf52820dongle\nrf52820dongle_nrf52820.dts:25 */
		};

		/* node '/leds/led_1' defined in nrf\boards\nordic\nrf52820dongle\nrf52820dongle_nrf52820.dts:27 */
		led1_red: led_1 {
			gpios = < &gpio0 0x14 0x1 >; /* in nrf\boards\nordic\nrf52820dongle\nrf52820dongle_nrf52820.dts:28 */
			label = "Red LED 1";         /* in nrf\boards\nordic\nrf52820dongle\nrf52820dongle_nrf52820.dts:29 */
		};

		/* node '/leds/led_2' defined in nrf\boards\nordic\nrf52820dongle\nrf52820dongle_nrf52820.dts:31 */
		led1_green: led_2 {
			gpios = < &gpio0 0x1c 0x1 >; /* in nrf\boards\nordic\nrf52820dongle\nrf52820dongle_nrf52820.dts:32 */
			label = "Green LED 1";       /* in nrf\boards\nordic\nrf52820dongle\nrf52820dongle_nrf52820.dts:33 */
		};

		/* node '/leds/led_3' defined in nrf\boards\nordic\nrf52820dongle\nrf52820dongle_nrf52820.dts:35 */
		led1_blue: led_3 {
			gpios = < &gpio0 0x1d 0x1 >; /* in nrf\boards\nordic\nrf52820dongle\nrf52820dongle_nrf52820.dts:36 */
			label = "Blue LED 1";        /* in nrf\boards\nordic\nrf52820dongle\nrf52820dongle_nrf52820.dts:37 */
		};
	};

	/* node '/buttons' defined in nrf\boards\nordic\nrf52820dongle\nrf52820dongle_nrf52820.dts:41 */
	buttons {
		compatible = "gpio-keys"; /* in nrf\boards\nordic\nrf52820dongle\nrf52820dongle_nrf52820.dts:42 */

		/* node '/buttons/button_0' defined in nrf\boards\nordic\nrf52820dongle\nrf52820dongle_nrf52820.dts:43 */
		button0: button_0 {
			gpios = < &gpio0 0x11 0x11 >;   /* in nrf\boards\nordic\nrf52820dongle\nrf52820dongle_nrf52820.dts:44 */
			label = "Push button switch 0"; /* in nrf\boards\nordic\nrf52820dongle\nrf52820dongle_nrf52820.dts:45 */
		};
	};

	/* node '/usb_audio2' defined in D:/Inzynierka_V2/Kody_testowe/bap_broadcast_source/app.overlay:10 */
	uac2_broadcaster: usb_audio2 {
		compatible = "zephyr,uac2"; /* in D:/Inzynierka_V2/Kody_testowe/bap_broadcast_source/app.overlay:11 */
		status = "okay";            /* in D:/Inzynierka_V2/Kody_testowe/bap_broadcast_source/app.overlay:12 */
		full-speed;                 /* in D:/Inzynierka_V2/Kody_testowe/bap_broadcast_source/app.overlay:13 */
		audio-function = < 0xff >;  /* in D:/Inzynierka_V2/Kody_testowe/bap_broadcast_source/app.overlay:14 */

		/* node '/usb_audio2/aclk' defined in D:/Inzynierka_V2/Kody_testowe/bap_broadcast_source/app.overlay:20 */
		uac_aclk: aclk {
			compatible = "zephyr,uac2-clock-source"; /* in D:/Inzynierka_V2/Kody_testowe/bap_broadcast_source/app.overlay:21 */
			clock-type = "internal-programmable";    /* in D:/Inzynierka_V2/Kody_testowe/bap_broadcast_source/app.overlay:22 */
			frequency-control = "read-only";         /* in D:/Inzynierka_V2/Kody_testowe/bap_broadcast_source/app.overlay:23 */
			sampling-frequencies = < 0xbb80 >;       /* in D:/Inzynierka_V2/Kody_testowe/bap_broadcast_source/app.overlay:24 */
			sof-synchronized;                        /* in D:/Inzynierka_V2/Kody_testowe/bap_broadcast_source/app.overlay:28 */
			phandle = < 0x7 >;                       /* in D:/Inzynierka_V2/Kody_testowe/bap_broadcast_source/app.overlay:34 */
		};

		/* node '/usb_audio2/out_terminal' defined in D:/Inzynierka_V2/Kody_testowe/bap_broadcast_source/app.overlay:32 */
		out_terminal: out_terminal {
			compatible = "zephyr,uac2-input-terminal"; /* in D:/Inzynierka_V2/Kody_testowe/bap_broadcast_source/app.overlay:33 */
			clock-source = < &uac_aclk >;              /* in D:/Inzynierka_V2/Kody_testowe/bap_broadcast_source/app.overlay:34 */
			terminal-type = < 0x101 >;                 /* in D:/Inzynierka_V2/Kody_testowe/bap_broadcast_source/app.overlay:35 */
			front-left;                                /* in D:/Inzynierka_V2/Kody_testowe/bap_broadcast_source/app.overlay:36 */
			front-right;                               /* in D:/Inzynierka_V2/Kody_testowe/bap_broadcast_source/app.overlay:37 */
			phandle = < 0x8 >;                         /* in D:/Inzynierka_V2/Kody_testowe/bap_broadcast_source/app.overlay:43 */
		};

		/* node '/usb_audio2/headphones' defined in D:/Inzynierka_V2/Kody_testowe/bap_broadcast_source/app.overlay:41 */
		broadcaster_output: headphones {
			compatible = "zephyr,uac2-output-terminal"; /* in D:/Inzynierka_V2/Kody_testowe/bap_broadcast_source/app.overlay:42 */
			data-source = < &out_terminal >;            /* in D:/Inzynierka_V2/Kody_testowe/bap_broadcast_source/app.overlay:43 */
			clock-source = < &uac_aclk >;               /* in D:/Inzynierka_V2/Kody_testowe/bap_broadcast_source/app.overlay:44 */
			terminal-type = < 0x300 >;                  /* in D:/Inzynierka_V2/Kody_testowe/bap_broadcast_source/app.overlay:45 */
		};

		/* node '/usb_audio2/out_interface' defined in D:/Inzynierka_V2/Kody_testowe/bap_broadcast_source/app.overlay:48 */
		as_iso_out: out_interface {
			compatible = "zephyr,uac2-audio-streaming"; /* in D:/Inzynierka_V2/Kody_testowe/bap_broadcast_source/app.overlay:49 */
			linked-terminal = < &out_terminal >;        /* in D:/Inzynierka_V2/Kody_testowe/bap_broadcast_source/app.overlay:50 */
			subslot-size = < 0x2 >;                     /* in D:/Inzynierka_V2/Kody_testowe/bap_broadcast_source/app.overlay:51 */
			bit-resolution = < 0x10 >;                  /* in D:/Inzynierka_V2/Kody_testowe/bap_broadcast_source/app.overlay:52 */
		};
	};
};
